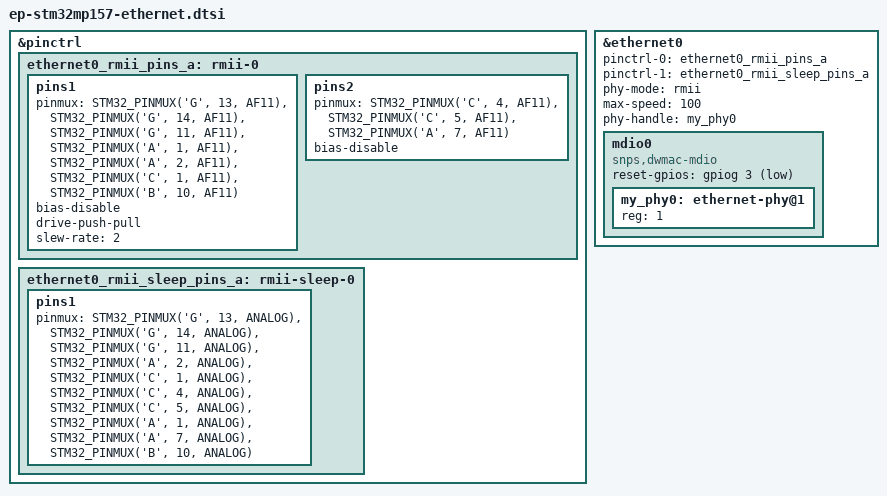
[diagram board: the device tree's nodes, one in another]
// SPDX-License-Identifier: (GPL-2.0+ OR BSD-3-Clause)
/*
 * Copyright (C) STMicroelectronics 2017 - All Rights Reserved
 * Author: Ludovic Barre <ludovic.barre@st.com> for STMicroelectronics.
 */
#include <dt-bindings/pinctrl/stm32-pinfunc.h>

&pinctrl {
	ethernet0_rmii_pins_a: rmii-0 {
		pins1 {
			pinmux = <STM32_PINMUX('G', 13, AF11)>, /* ETH1_RMII_TXD0 */
				 <STM32_PINMUX('G', 14, AF11)>, /* ETH1_RMII_TXD1 */
				 <STM32_PINMUX('G', 11, AF11)>, /* ETH1_RMII_TX_EN */
				 <STM32_PINMUX('A', 1, AF11)>,   /* ETH1_RMII_REF_CLK */
				 <STM32_PINMUX('A', 2, AF11)>,  /* ETH1_MDIO */
				 <STM32_PINMUX('C', 1, AF11)>,  /* ETH1_MDC */
				 <STM32_PINMUX('B', 10, AF11)>;  /* ETH1_GMII_RX_ER */
			bias-disable;
			drive-push-pull;
			slew-rate = <2>;
		};
		pins2 {
			pinmux = <STM32_PINMUX('C', 4, AF11)>,  /* ETH1_RMII_RXD0 */
				 <STM32_PINMUX('C', 5, AF11)>,  /* ETH1_RMII_RXD1 */
				 <STM32_PINMUX('A', 7, AF11)>;  /* ETH1_RMII_CRS_DV */
			bias-disable;
		};
	};

	ethernet0_rmii_sleep_pins_a: rmii-sleep-0 {
		pins1 {
			pinmux = <STM32_PINMUX('G', 13, ANALOG)>, /* ETH1_RMII_TXD0 */
				 <STM32_PINMUX('G', 14, ANALOG)>, /* ETH1_RMII_TXD1 */
				 <STM32_PINMUX('G', 11, ANALOG)>, /* ETH1_RMII_TX_EN */
				 <STM32_PINMUX('A', 2, ANALOG)>,  /* ETH1_MDIO */
				 <STM32_PINMUX('C', 1, ANALOG)>,  /* ETH1_MDC */
				 <STM32_PINMUX('C', 4, ANALOG)>,  /* ETH1_RMII_RXD0 */
				 <STM32_PINMUX('C', 5, ANALOG)>,  /* ETH1_RMII_RXD1 */
				 <STM32_PINMUX('A', 1, ANALOG)>,  /* ETH1_RMII_REF_CLK */
				 <STM32_PINMUX('A', 7, ANALOG)>,  /* ETH1_RMII_CRS_DV */
				 <STM32_PINMUX('B', 10, ANALOG)>;  /* ETH1_GMII_RX_ER */
		};
	};
};
	
&ethernet0 {
	status = "okay";
	pinctrl-0 = <&ethernet0_rmii_pins_a>;
	pinctrl-1 = <&ethernet0_rmii_sleep_pins_a>;
	pinctrl-names = "default", "sleep";
	phy-mode = "rmii";
	max-speed = <100>;
	phy-handle = <&my_phy0>;

	mdio0 {
		#address-cells = <1>;
		#size-cells = <0>;
		compatible = "snps,dwmac-mdio";
		reset-gpios = <&gpiog 3 GPIO_ACTIVE_LOW>;

		my_phy0: ethernet-phy@1 {
			reg = <1>;
						
		};
	};
};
